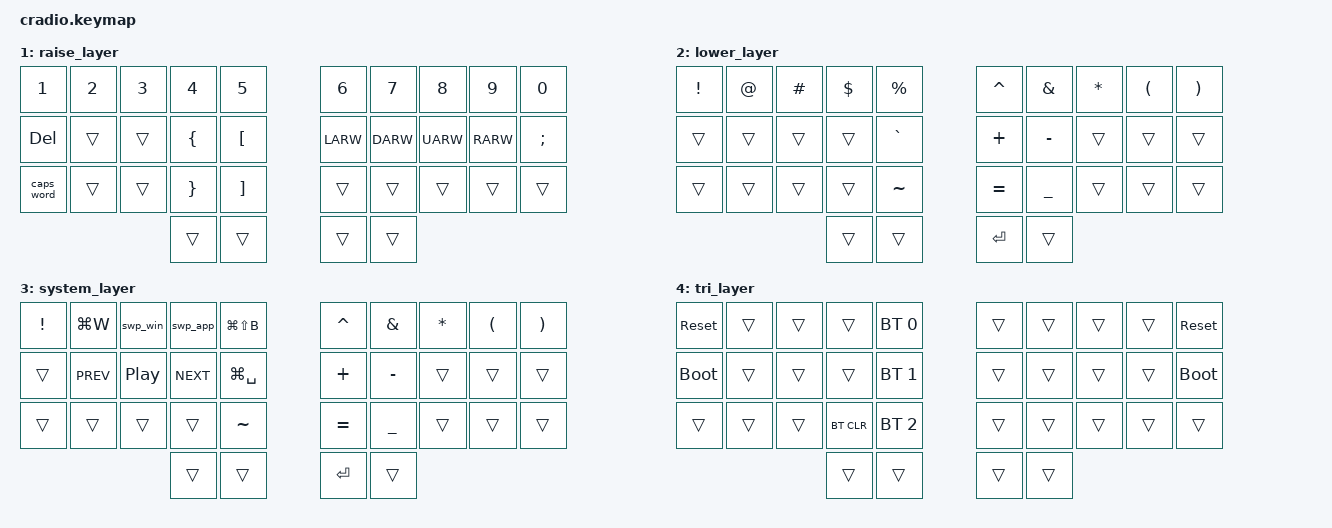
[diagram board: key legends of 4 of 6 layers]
// Copyright (c) 2022 The ZMK Contributors
// SPDX-License-Identifier: MIT

// TODO
// - Fix system layer
// - Give pinky shift a shot, but not right now
// - Add swe char combos
// - Make alternative layouts togglable
#include <behaviors.dtsi>
#include <dt-bindings/zmk/keys.h>
#include <dt-bindings/zmk/bt.h>

//                    KEY POSITIONS
//
//    ╭────────────────────╮ ╭────────────────────╮
//    │  0   1   2   3   4 │ │  5   6   7   8   9 │
//    │ 10  11  12  13  14 │ │ 15  16  17  18  19 │
//    │ 20  21  22  23  24 │ │ 25  26  27  28  29 │
//    ╰───────────╮ 30  31 │ │ 32  33 ╭───────────╯
//                ╰────────╯ ╰────────╯

#define LEFT_KEYS 0 1 2 3 4 10 11 12 13 14 20 21 22 23 24  // left-hand keys
#define RIGHT_KEYS 5 6 7 8 9 15 16 17 18 19 25 26 27 28 29  // right-hand keys

// Home row mods macro
#define HRML(k1,k2,k3,k4) &hrm_l LCTRL k1  &hrm_l LALT k2  &hrm_l LGUI k3  &hrm_l LSHFT k4
#define HRMR(k1,k2,k3,k4) &hrm_r RSHIFT k1  &hrm_r RGUI k2  &hrm_r LALT k3  &hrm_r RCTRL k4

#define QUICK_TAP_MS 150

&caps_word {
    continue-list = <UNDERSCORE MINUS BACKSPACE>;
};

/* &lt {  // layer-tap config */
/*     flavor = "hold-preferred"; */
/*     tapping-term-ms = <200>; */
/*     quick-tap-ms = <200>; */
/* }; */

&lt {
  flavor = "balanced";
  tapping-term-ms = <200>;
  quick-tap-ms = <QUICK_TAP_MS>;
};

#define COMBO(NAME, BINDINGS, KEYPOS, TIMEOUT) \
  combo_##NAME { \
    timeout-ms = <TIMEOUT>; \
    bindings = <BINDINGS>; \
    key-positions = <KEYPOS>; \
    layers = <0 5>; \
  };

#define MACRO(name, keys)                  \
    name: name##_macro {                   \
        label = #name;                     \
        compatible = "zmk,behavior-macro"; \
        wait-ms = <1>;                     \
        tap-ms = <1>;                      \
        #binding-cells = <0>;              \
        bindings = <keys>;                 \
    };
/ {
    behaviors {
        ht: hold_tap {
            compatible = "zmk,behavior-hold-tap";
            #binding-cells = <2>;
            flavor = "balanced";
            tapping-term-ms = <200>;
            quick-tap-ms = <QUICK_TAP_MS>;
            require-prior-idle-ms = <80>;
            bindings = <&kp>, <&kp>;
        };

        hrm_l: left_homerow_mods {
            compatible = "zmk,behavior-hold-tap";
            label = "HOMEROW_MODS_LEFT";
            #binding-cells = <2>;
            flavor = "balanced";
            tapping-term-ms = <200>;
            hold-trigger-key-positions = <RIGHT_KEYS>;
            hold-trigger-on-release;
            bindings = <&kp>, <&kp>;
        };

        hrm_r: right_homerow_mods {
            compatible = "zmk,behavior-hold-tap";
            label = "HOMEROW_MODS_RIGHT";
            #binding-cells = <2>;
            flavor = "balanced";
            tapping-term-ms = <200>;
            hold-trigger-key-positions = <LEFT_KEYS>;
            hold-trigger-on-release;
            bindings = <&kp>, <&kp>;
        };

        um: umlaut {
            compatible = "zmk,behavior-mod-morph";
            #binding-cells = <0>;
            bindings = <&kp LA(U)>, <&kp LA(U)>;
            mods = <(MOD_LSFT|MOD_RSFT)>;
        };

        swp_win: swapper_win {
            compatible = "zmk,behavior-tri-state";
            label = "WINSWAP";
            #binding-cells = <0>;
            bindings = <&kt LGUI>, <&kp TAB>, <&kt LGUI>;
        };

        swp_app: swapper_app {
            compatible = "zmk,behavior-tri-state";
            label = "APPSWAP";
            #binding-cells = <0>;
            bindings = <&kt LGUI>, <&kp GRAVE>, <&kt LGUI>;
        };
    };

    conditional_layers {
        compatible = "zmk,conditional-layers";
        tri_layer {
            if-layers = <1 3>;
            then-layer = <4>;
        };
    };

//                    KEY POSITIONS
//
//    ╭────────────────────╮ ╭────────────────────╮
//    │  0   1   2   3   4 │ │  5   6   7   8   9 │
//    │ 10  11  12  13  14 │ │ 15  16  17  18  19 │
//    │ 20  21  22  23  24 │ │ 25  26  27  28  29 │
//    ╰───────────╮ 30  31 │ │ 32  33 ╭───────────╯
//                ╰────────╯ ╰────────╯

    combos { 
        compatible = "zmk,combos";
        COMBO(esc, &ht RG(RSHFT) ESC, 16 17, 30)
        COMBO(eql, &kp EQUAL, 16 18, 40)
        COMBO(tab, &ht RG(RALT) TAB, 17 18, 40)
        COMBO(copy, &kp LG(C), 21 22, 30)
        COMBO(paste, &kp LG(V), 22 23, 30)
        COMBO(cut, &kp LG(X), 21 23, 40)
        COMBO(undo, &kp LG(Z), 20 21, 40)

        COMBO(arrow, &arrow, 27 28, 45)
        COMBO(not_equal, &not_equal, 6 7, 45)
        COMBO(or, &kp PIPE, 3 4, 45)
        COMBO(and, &kp AMPS, 5 6, 45)

        COMBO(caps_word, &caps_word, 13 16, 45)
        COMBO(caps_word_2, &caps_word, 6 7 8, 45)

        COMBO(single_quote, &kp SQT, 6 16, 45)
        COMBO(double_quote, &kp DQT, 16 26, 45)

        COMBO(backslash, &kp BSLH, 7 18, 45)

        COMBO(left_par, &ht LA(LGUI) LPAR, 11 12, 30)
        COMBO(right_par, &ht LG(LSHFT) RPAR, 12 13, 30)
        COMBO(par_pair, &par_pair, 11 13, 30)
        COMBO(par_pair_in, &par_pair_in, 11 12 13, 30)

        COMBO(left_brace, &kp LBRC, 1 2, 45)
        COMBO(right_brace, &kp RBRC, 2 3, 45)
        COMBO(brace_pair, &brace_pair, 1 3, 45)
        COMBO(brace_pair_in, &brace_pair_in, 1 2 3, 45)

        COMBO(swe_ao, &swe_ao, 10 19, 45)
        COMBO(swe_ae, &swe_ae, 10 17, 45)
        COMBO(swe_oe, &swe_oe, 17 19, 45)
    };

    macros {
        MACRO(arrow, &kp MINUS &kp GT)
        MACRO(not_equal, &kp EXCL &kp EQUAL)
        MACRO(par_pair, &kp LPAR &kp RPAR)
        MACRO(par_pair_in, &kp LPAR &kp RPAR &kp LARW)
        MACRO(brace_pair, &kp LBRC &kp RBRC)
        MACRO(brace_pair_in, &kp LBRC &kp SPACE &kp SPACE &kp RBRC &kp LARW &kp LARW)

        MACRO(swe_ao, &kp LA(A))
        MACRO(swe_ae, &um &kp A)
        MACRO(swe_oe, &um &kp O)
    };

    keymap {
        compatible = "zmk,keymap";
        default_layer {
            bindings = <
        //╭──────────┬──────────┬──────────┬──────────┬──────────╮   ╭──────────┬──────────┬──────────┬──────────┬──────────╮
            &kp Q      &kp W      &kp F      &kp P      &kp B          &kp J      &kp L      &kp U      &kp Y      &kp SEMI
        //├──────────┼──────────┼──────────┼──────────┼──────────┤   ├──────────┼──────────┼──────────┼──────────┼──────────┤
            HRML(A,        R,         S,         T)     &kp G          &kp M      HRMR(N,        E,         I,        O)
        //├──────────┼──────────┼──────────┼──────────┼──────────┤   ├──────────┼──────────┼──────────┼──────────┼──────────┤
            &kp Z      &kp X      &kp C      &kp D      &kp V          &kp K      &kp H      &kp COMMA  &kp DOT    &kp FSLH
        //╰──────────┴──────────┴──────────┼──────────┼──────────┤   ├──────────┼──────────┼──────────┴──────────┴──────────╯
                                             &lt 3 TAB  &lt 2 SPC      &lt 1 ESC  &lt 1 BSPC
        //                                 ╰──────────┴──────────╯   ╰──────────┴──────────╯
            >;
        };

        raise_layer {
            bindings = <
        //╭──────────┬──────────┬──────────┬──────────┬──────────╮   ╭──────────┬──────────┬──────────┬──────────┬──────────╮
            &kp N1      &kp N2     &kp N3     &kp N4     &kp N5        &kp N6     &kp N7     &kp N8      &kp N9    &kp N0
        //├──────────┼──────────┼──────────┼──────────┼──────────┤   ├──────────┼──────────┼──────────┼──────────┼──────────┤
            &kp DEL    &trans     &trans     &kp LBRC   &kp LBKT       &kp LARW   &kp DARW   &kp UARW   &kp RARW   &kp SEMI
        //├──────────┼──────────┼──────────┼──────────┼──────────┤   ├──────────┼──────────┼──────────┼──────────┼──────────┤
           &caps_word  &trans     &trans     &kp RBRC   &kp RBKT       &trans     &trans     &trans     &trans     &trans
        //╰──────────┴──────────┴──────────┼──────────┼──────────┤   ├──────────┼──────────┼──────────┴──────────┴──────────╯
                                             &trans     &trans         &trans     &trans
        //                                 ╰──────────┴──────────╯   ╰──────────┴──────────╯
            >;
        };

        lower_layer {
            bindings = <
        //╭──────────┬──────────┬──────────┬──────────┬──────────╮   ╭──────────┬──────────┬──────────┬──────────┬──────────╮
            &kp EXCL   &kp AT     &kp HASH   &kp DLLR   &kp PRCNT      &kp CARET  &kp AMPS   &kp ASTRK  &kp LPAR   &kp RPAR
        //├──────────┼──────────┼──────────┼──────────┼──────────┤   ├──────────┼──────────┼──────────┼──────────┼──────────┤
            &trans     &trans     &trans     &trans     &kp GRAVE      &kp PLUS   &kp MINUS  &trans     &trans     &trans
        //├──────────┼──────────┼──────────┼──────────┼──────────┤   ├──────────┼──────────┼──────────┼──────────┼──────────┤
            &trans     &trans     &trans     &trans     &kp TILDE      &kp EQUAL  &kp UNDER  &trans     &trans     &trans
        //╰──────────┴──────────┴──────────┼──────────┼──────────┤   ├──────────┼──────────┼──────────┴──────────┴──────────╯
                                             &trans     &trans         &kp ENTER  &trans
        //                                 ╰──────────┴──────────╯   ╰──────────┴──────────╯
            >;
        };

        system_layer {
            bindings = <
        //╭──────────┬──────────┬──────────┬──────────┬──────────╮   ╭──────────┬──────────┬──────────┬──────────┬──────────╮
            &kp EXCL   &kp LG(W)  &swp_win   &swp_app  &kp LG(LS(B))   &kp CARET  &kp AMPS   &kp ASTRK  &kp LPAR   &kp RPAR
        //├──────────┼──────────┼──────────┼──────────┼──────────┤   ├──────────┼──────────┼──────────┼──────────┼──────────┤
            &trans     &kp C_PREV &kp C_PP  &kp C_NEXT &kp LG(SPACE)   &kp PLUS   &kp MINUS  &trans     &trans     &trans
        //├──────────┼──────────┼──────────┼──────────┼──────────┤   ├──────────┼──────────┼──────────┼──────────┼──────────┤
            &trans     &trans     &trans     &trans     &kp TILDE      &kp EQUAL  &kp UNDER  &trans     &trans     &trans
        //╰──────────┴──────────┴──────────┼──────────┼──────────┤   ├──────────┼──────────┼──────────┴──────────┴──────────╯
                                             &trans     &trans         &kp ENTER  &trans
        //                                 ╰──────────┴──────────╯   ╰──────────┴──────────╯
            >;
        };

        tri_layer {
            bindings = <
        //╭──────────┬──────────┬──────────┬──────────┬──────────╮   ╭──────────┬──────────┬──────────┬──────────┬──────────╮
        //│ RESET    │          │          │          │PROFILE 0 │   │          │          │          │          │  RESET   │
           &sys_reset  &trans     &trans     &trans    &bt BT_SEL 0    &trans     &trans     &trans     &trans    &sys_reset
        //├──────────┼──────────┼──────────┼──────────┼──────────┤   ├──────────┼──────────┼──────────┼──────────┼──────────┤
        //│BOOTLOADER│          │          │          │PROFILE 1 │   │          │          │          │          │BOOTLOADER│
          &bootloader  &trans     &trans     &trans    &bt BT_SEL 1    &trans     &trans     &trans     &trans    &bootloader
        //├──────────┼──────────┼──────────┼──────────┼──────────┤   ├──────────┼──────────┼──────────┼──────────┼──────────┤
        //│          │          │          │ CLEAR BT │PROFILE 2 │   │          │          │          │          │          │
            &trans     &trans     &trans    &bt BT_CLR &bt BT_SEL 2    &trans     &trans     &trans     &trans     &trans
        //╰──────────┴──────────┴──────────┼──────────┼──────────┤   ├──────────┼──────────┼──────────┴──────────┴──────────╯
                                             &trans     &trans         &trans     &trans
        //                                 ╰──────────┴──────────╯   ╰──────────┴──────────╯
            >;
        };

        gallium_layer {
            bindings = <
        //╭──────────┬──────────┬──────────┬──────────┬──────────╮   ╭──────────┬──────────┬──────────┬──────────┬──────────╮
            &kp B      &kp L      &kp D      &kp C      &kp V          &kp J      &kp F      &kp O      &kp U      &kp SEMI
        //├──────────┼──────────┼──────────┼──────────┼──────────┤   ├──────────┼──────────┼──────────┼──────────┼──────────┤
            HRML(N,        R,         T,         S)     &kp G          &kp Y      HRMR(H,        A,         E,        I)
        //├──────────┼──────────┼──────────┼──────────┼──────────┤   ├──────────┼──────────┼──────────┼──────────┼──────────┤
            &kp X      &kp Q      &kp M      &kp W      &kp Z          &kp K      &kp P      &kp COMMA  &kp DOT    &kp FSLH
        //╰──────────┴──────────┴──────────┼──────────┼──────────┤   ├──────────┼──────────┼──────────┴──────────┴──────────╯
                                             &lt 2 TAB &lt 2 SPACE     &lt 1 ESC  &lt 1 BSPC
        //                                 ╰──────────┴──────────╯   ╰──────────┴──────────╯
            >;
        };
    };
};
// vim:ft=dts
